# CY8C5888LTI_LP097 register map
File version: 0.1
Registers are 8-bit, read-write, no defined reset value unless marked. A register's access mark holds for its fields unless they carry their own. Offsets are from the block's base; [hi:lo] are bit positions; 'fields as' and 'values as' point back to an identical list.

## TRIG_PERIOD
Base 0x00000000
0x40006504 TRIG_PERIOD_COUNTER 32-bit — UDB.A0 - Current Down Counter Value
0x40006524 TRIG_PERIOD_PERIOD 32-bit — UDB.D0 - Assigned Period
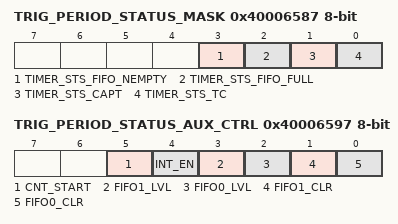
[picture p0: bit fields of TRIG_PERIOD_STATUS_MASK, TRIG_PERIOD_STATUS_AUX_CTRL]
0x40006587 TRIG_PERIOD_STATUS_MASK — UDB Status bits Interrupt Mask Enable Register
  [3] TIMER_STS_FIFO_NEMPTY ro — FIFO Empty status
  [2] TIMER_STS_FIFO_FULL ro — FIFO Full Status
  [1] TIMER_STS_CAPT ro — Enables the Interrupt on Capture
  [0] TIMER_STS_TC ro — Enables the Interrupt on TC
0x40006597 TRIG_PERIOD_STATUS_AUX_CTRL — UDB Auxilliary Control Register
  [5] CNT_START — FIFO0 clear
    0=E_CNT_START0 (Disable counter); 1=E_CNT_START1 (Enable counter)
  [4] INT_EN
    0=E_INT_EN0 (Interrupt disabled); 1=E_INT_EN1 (Interrupt enabled)
  [3] FIFO1_LVL — FIFO level
    0=E_FIFO_LVL_0 (FIFO LVL: input mode: FIFO not full; output mode: FIFO not empty); 1=E_FIFO_LVL_1 (FIFO LVL: input mode: FIFO at least 1/2 empty; output mode: FIFO at least 1/2 full)
  [2] FIFO0_LVL — FIFO level
    values as FIFO1_LVL
  [1] FIFO1_CLR — FIFO1 clear
    0=E_FIFO_CLR_0 (Normal FIFO operation); 1=E_FIFO_CLR_1 (Clear FIFO state)
  [0] FIFO0_CLR — FIFO0 clear
    values as FIFO1_CLR

## RESET_RDY_TIMER
Base 0x00000000
0x40006476 RESET_RDY_TIMER_CONTROL_REG

## Trigger_Count
Base 0x00000000
0x40006404 Trigger_Count_COUNTER 16-bit — UDB.A0 - Current Counter Value
0x40006424 Trigger_Count_PERIOD 16-bit — UDB.D0 - Assigned Period
0x40006434 Trigger_Count_COMPARE 16-bit — UDB.D1 - Assigned Compare Value
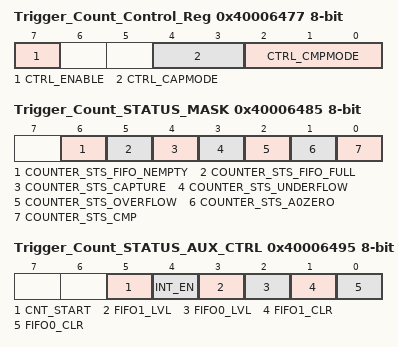
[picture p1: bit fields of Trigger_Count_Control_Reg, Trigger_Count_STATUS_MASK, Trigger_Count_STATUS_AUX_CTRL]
0x40006477 Trigger_Count_Control_Reg — UDB Control Register - Assigned Control Register Value
  [7] CTRL_ENABLE — Enable Counter
  [4:3] CTRL_CAPMODE — Capture mode
  [2:0] CTRL_CMPMODE — Compare mode
0x40006485 Trigger_Count_STATUS_MASK — UDB Status bits Interrupt Mask Enable Register
  [6] COUNTER_STS_FIFO_NEMPTY — FIFO Not Empty Status
  [5] COUNTER_STS_FIFO_FULL — FIFO Full Status
  [4] COUNTER_STS_CAPTURE — Capture Status
  [3] COUNTER_STS_UNDERFLOW — Underflow status
  [2] COUNTER_STS_OVERFLOW — Overflow status
  [1] COUNTER_STS_A0ZERO — A0 Zero ouput status
  [0] COUNTER_STS_CMP — Compare output status
0x40006495 Trigger_Count_STATUS_AUX_CTRL — UDB Auxilliary Control Register
  [5] CNT_START — FIFO0 clear
    0=E_CNT_START0 (Disable counter); 1=E_CNT_START1 (Enable counter)
  [4] INT_EN
    0=E_INT_EN0 (Interrupt disabled); 1=E_INT_EN1 (Interrupt enabled)
  [3] FIFO1_LVL — FIFO level
    0=E_FIFO_LVL_0 (FIFO LVL: input mode: FIFO not full; output mode: FIFO not empty); 1=E_FIFO_LVL_1 (FIFO LVL: input mode: FIFO at least 1/2 empty; output mode: FIFO at least 1/2 full)
  [2] FIFO0_LVL — FIFO level
    values as FIFO1_LVL
  [1] FIFO1_CLR — FIFO1 clear
    0=E_FIFO_CLR_0 (Normal FIFO operation); 1=E_FIFO_CLR_1 (Clear FIFO state)
  [0] FIFO0_CLR — FIFO0 clear
    values as FIFO1_CLR

## Frame_Period_Timer
Base 0x00000000
0x40006407 Frame_Period_Timer_COUNTER 32-bit — UDB.A0 - Current Down Counter Value
0x40006427 Frame_Period_Timer_PERIOD 32-bit — UDB.D0 - Assigned Period
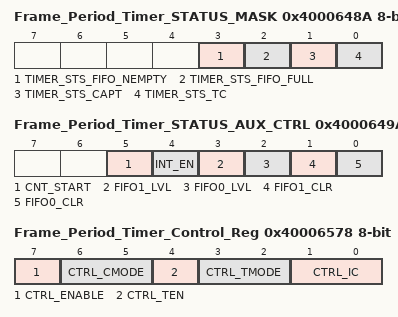
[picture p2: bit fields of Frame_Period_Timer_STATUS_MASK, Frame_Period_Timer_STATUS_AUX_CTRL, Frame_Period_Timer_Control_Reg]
0x4000648A Frame_Period_Timer_STATUS_MASK — UDB Status bits Interrupt Mask Enable Register
  [3] TIMER_STS_FIFO_NEMPTY ro — FIFO Empty status
  [2] TIMER_STS_FIFO_FULL ro — FIFO Full Status
  [1] TIMER_STS_CAPT ro — Enables the Interrupt on Capture
  [0] TIMER_STS_TC ro — Enables the Interrupt on TC
0x4000649A Frame_Period_Timer_STATUS_AUX_CTRL — UDB Auxilliary Control Register
  [5] CNT_START — FIFO0 clear
    0=E_CNT_START0 (Disable counter); 1=E_CNT_START1 (Enable counter)
  [4] INT_EN
    0=E_INT_EN0 (Interrupt disabled); 1=E_INT_EN1 (Interrupt enabled)
  [3] FIFO1_LVL — FIFO level
    0=E_FIFO_LVL_0 (FIFO LVL: input mode: FIFO not full; output mode: FIFO not empty); 1=E_FIFO_LVL_1 (FIFO LVL: input mode: FIFO at least 1/2 empty; output mode: FIFO at least 1/2 full)
  [2] FIFO0_LVL — FIFO level
    values as FIFO1_LVL
  [1] FIFO1_CLR — FIFO1 clear
    0=E_FIFO_CLR_0 (Normal FIFO operation); 1=E_FIFO_CLR_1 (Clear FIFO state)
  [0] FIFO0_CLR — FIFO0 clear
    values as FIFO1_CLR
0x40006578 Frame_Period_Timer_Control_Reg — UDB Control Register - Assigned Control Register Value
  [7] CTRL_ENABLE — Enable the Timer
  [6:5] CTRL_CMODE — Capture Mode
  [4] CTRL_TEN — Trigger Enable Bit
  [3:2] CTRL_TMODE — Trigger Mode
  [1:0] CTRL_IC — Interrupt Count

## FRAME_TRIG_Reg
Base 0x00000000
0x40006475 FRAME_TRIG_Reg_CONTROL_REG

## STAGE_PERIOD
Base 0x00000000
0x4000647D STAGE_PERIOD_CONTROL_REG

## STAGE_COACH
Base 0x00000000
0x40006508 STAGE_COACH_COUNTER 24-bit — UDB.A0 - Current Counter Value
0x40006528 STAGE_COACH_PERIOD 24-bit — UDB.D0 - Assigned Period
0x40006538 STAGE_COACH_COMPARE 24-bit — UDB.D1 - Assigned Compare Value
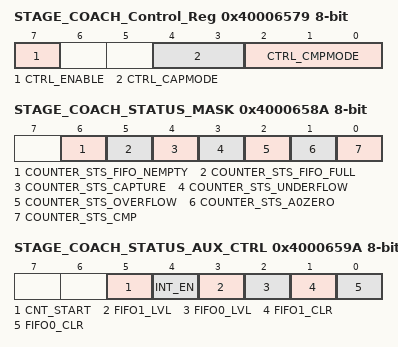
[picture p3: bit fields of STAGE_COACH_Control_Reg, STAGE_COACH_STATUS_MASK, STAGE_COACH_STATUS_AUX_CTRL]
0x40006579 STAGE_COACH_Control_Reg — UDB Control Register - Assigned Control Register Value
  [7] CTRL_ENABLE — Enable Counter
  [4:3] CTRL_CAPMODE — Capture mode
  [2:0] CTRL_CMPMODE — Compare mode
0x4000658A STAGE_COACH_STATUS_MASK — UDB Status bits Interrupt Mask Enable Register
  [6] COUNTER_STS_FIFO_NEMPTY — FIFO Not Empty Status
  [5] COUNTER_STS_FIFO_FULL — FIFO Full Status
  [4] COUNTER_STS_CAPTURE — Capture Status
  [3] COUNTER_STS_UNDERFLOW — Underflow status
  [2] COUNTER_STS_OVERFLOW — Overflow status
  [1] COUNTER_STS_A0ZERO — A0 Zero ouput status
  [0] COUNTER_STS_CMP — Compare output status
0x4000659A STAGE_COACH_STATUS_AUX_CTRL — UDB Auxilliary Control Register
  [5] CNT_START — FIFO0 clear
    0=E_CNT_START0 (Disable counter); 1=E_CNT_START1 (Enable counter)
  [4] INT_EN
    0=E_INT_EN0 (Interrupt disabled); 1=E_INT_EN1 (Interrupt enabled)
  [3] FIFO1_LVL — FIFO level
    0=E_FIFO_LVL_0 (FIFO LVL: input mode: FIFO not full; output mode: FIFO not empty); 1=E_FIFO_LVL_1 (FIFO LVL: input mode: FIFO at least 1/2 empty; output mode: FIFO at least 1/2 full)
  [2] FIFO0_LVL — FIFO level
    values as FIFO1_LVL
  [1] FIFO1_CLR — FIFO1 clear
    0=E_FIFO_CLR_0 (Normal FIFO operation); 1=E_FIFO_CLR_1 (Clear FIFO state)
  [0] FIFO0_CLR — FIFO0 clear
    values as FIFO1_CLR

## Z_TRIG_Reg
Base 0x00000000
0x40006473 Z_TRIG_Reg_CONTROL_REG
